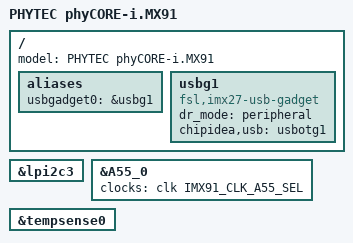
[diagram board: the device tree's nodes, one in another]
// SPDX-License-Identifier: (GPL-2.0+ OR MIT)
/*
 * Copyright (C) 2026 PHYTEC Messtechnik GmbH
 * Author: Primoz Fiser <primoz.fiser@norik.com>
 *
 */

#include "imx91-u-boot.dtsi"
#include "imx91-93-phyboard-segin-common-u-boot.dtsi"

&lpi2c3 {
	/delete-node/ eeprom@50;
};

/ {
	/*
	 * The phyCORE-i.MX91 u-boot uses the imx91-phyboard-segin.dts as
	 * reference, but does only make use of its SoM (phyCORE) contained
	 * periphery.
	 */
	model = "PHYTEC phyCORE-i.MX91";

	aliases {
		usbgadget0 = &usbg1;
	};

	usbg1: usbg1 {
		compatible = "fsl,imx27-usb-gadget";
		dr_mode = "peripheral";
		chipidea,usb = <&usbotg1>;
		status = "okay";
	};
};

&A55_0 {
	clocks = <&clk IMX91_CLK_A55_SEL>;
};

&tempsense0 {
	status = "okay";
};
